# CY8C4xxx register map
File version: 0.1
Registers are 8-bit, read-write, no defined reset value unless marked. A register's access mark holds for its fields unless they carry their own. Offsets are from the block's base; [hi:lo] are bit positions; {n}, {i} and the like mark numbered series; 'fields as' and 'values as' point back to an identical list.

## SAR — SAR ADC with Sequencer
Base 0x401A0000
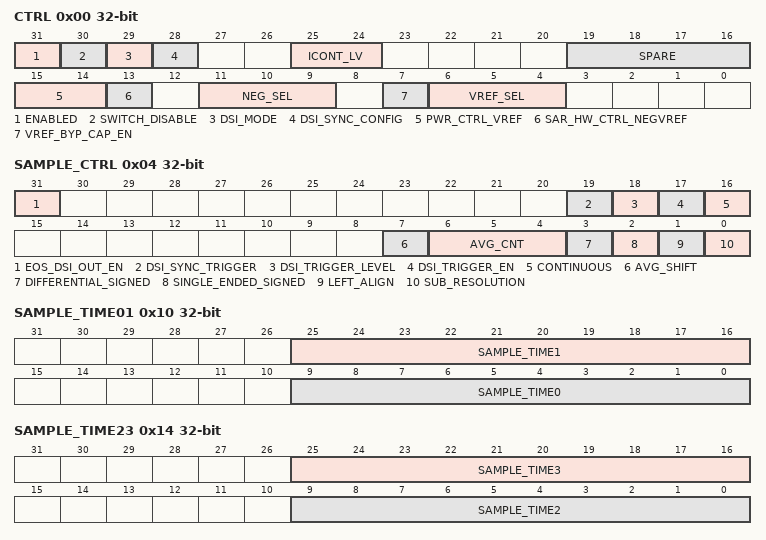
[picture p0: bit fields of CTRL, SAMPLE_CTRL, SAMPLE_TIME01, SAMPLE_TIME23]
0x00 CTRL 32-bit — Analog control register.
  [31] ENABLED — - 0: SAR IP disabled (put analog in power down and stop clocks), also can clear FW_TRIGGER and INJ_START_EN (if not tailgaiting) on write.?- 1: SAR IP enabled.
  [30] SWITCH_DISABLE — Disable SAR sequencer from enabling routing switches (note DSI and firmware can always close switches independent of this control)?- 0: Normal mode, SAR sequencer changes switches according to pin address in channel configurations?- 1: Switches disabled, SAR sequencer does not enable any switches, it is the responsibility of the firmware or UDBs (through DSI) to set the switches to route the signal to be converted through the SARMUX
  [29] DSI_MODE — SAR sequencer takes configuration from DSI signals (note this also has the same effect as SWITCH_DISABLE==1)?- 0: Normal mode, SAR sequencer operates according to CHAN_EN enables and CHAN_CONFIG channel configurations?- 1: CHAN_EN, INJ_START_EN and channel configurations in CHAN_CONFIG and INJ_CHAN_CONFIG are ignored
  [28] DSI_SYNC_CONFIG — - 0: bypass clock domain synchronisation of the DSI config signals.?- 1: synchronize the DSI config signals to peripheral clock domain.
  [25:24] ICONT_LV — SARADC low power mode.
    0=NORMAL_PWR; 1=HALF_PWR; 2=MORE_PWR; 3=QUARTER_PWR
  [19:16] SPARE — Spare controls, not yet designated, for late changes done with an ECO
  [15:14] PWR_CTRL_VREF — VREF buffer low power mode.
    0=NORMAL_PWR; 1=HALF_PWR; 2=THIRD_PWR; 3=QUARTER_PWR
  [13] SAR_HW_CTRL_NEGVREF — Hardware control: 0=only firmware control, 1=hardware control masked by firmware setting for VREF to NEG switch.
  [11:9] NEG_SEL — SARADC internal NEG selection for Single ended conversion
    0=VSSA_KELVIN; 1=ART_VSSA; 2=P1; 3=P3; 4=P5; 5=P7; 6=ACORE; 7=VREF
  [7] VREF_BYP_CAP_EN — VREF bypass cap enable for when VREF buffer is on
  [6:4] VREF_SEL — SARADC internal VREF selection.
    0=VREF0; 1=VREF1; 2=VREF2; 3=VREF_AROUTE; 4=VBGR; 5=VREF_EXT; 6=VDDA_DIV_2; 7=VDDA
0x04 SAMPLE_CTRL 32-bit — Sample control register.
  [31] EOS_DSI_OUT_EN — Enable to output EOS_INTR to DSI. When enabled each time EOS_INTR is set by the hardware also a pulse is send on the dsi_eos signal.
  [19] DSI_SYNC_TRIGGER — - 0: bypass clock domain synchronisation of the DSI trigger signal.?- 1: synchronize the DSI trigger signal to the SAR clock domain, if needed an edge detect is done in the peripheral clock domain.
  [18] DSI_TRIGGER_LEVEL — - 0: DSI trigger signal is a pulse input, a positive edge detected on the DSI trigger signal triggers a new scan.?- 1: DSI trigger signal is a level input, as long as the DSI trigger signal remains high the SAR will do continuous scans.
  [17] DSI_TRIGGER_EN — - 0: firmware trigger only: disable hardware (DSI) trigger.?- 1: enable hardware (DSI) trigger (e.g. from TCPWM, GPIO or UDB).
  [16] CONTINUOUS — - 0: Wait for next FW_TRIGGER (one shot) or hardware (DSI) trigger (e.g. from TPWM for periodic triggering) before scanning enabled channels.?- 1: Continuously scan enabled channels, ignore triggers.
  [7] AVG_SHIFT — Averaging shifting: after averaging the result is shifted right to fit in the sample resolution, i.e. 12 bits.
  [6:4] AVG_CNT — Averaging Count for channels that have over sampling enabled (AVG_EN). A channel will be sampled back to back (1<<(AVG_CNT+1)) = [2..256] times before the result is stored and the next enabled channel is sampled (1st order accumulate and dump filter).?If shifting is not enabled (AVG_SHIFT=0) then the result is forced to shift right so that is fits in 16 bits, so right shift is done by max(0,AVG_CNT-3).
  [3] DIFFERENTIAL_SIGNED — Output data from a differential conversion as a signed value
    0=UNSIGNED; 1=SIGNED
  [2] SINGLE_ENDED_SIGNED — Output data from a single ended conversion as a signed value
    0=UNSIGNED; 1=SIGNED
  [1] LEFT_ALIGN — Left align data in data[15:0], default data is right aligned in data[11:0], with sign extension to 16 bits if the channel is differential.
  [0] SUB_RESOLUTION — Conversion resolution for channels that have sub-resolution enabled (RESOLUTION=1) (otherwise resolution is 12-bit).
    0=Cy8B; 1=Cy10B
0x10 SAMPLE_TIME01 32-bit — Sample time specification ST0 and ST1
  [25:16] SAMPLE_TIME1
  [9:0] SAMPLE_TIME0 — Sample time0 (aperture) in ADC clock cycles.?Minimum sample time is 222ns, which is 4 cycles with an 18MHz clock. Minimum legal value in this register is 1.
0x14 SAMPLE_TIME23 32-bit — Sample time specification ST2 and ST3
  [25:16] SAMPLE_TIME3, [9:0] SAMPLE_TIME2
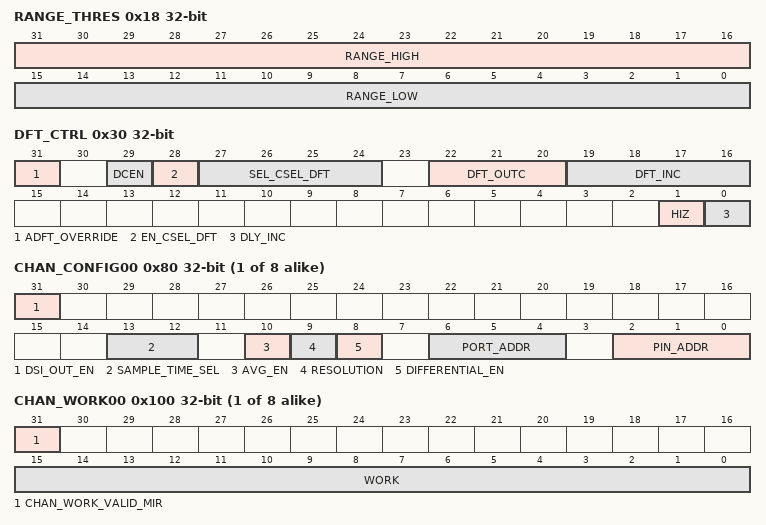
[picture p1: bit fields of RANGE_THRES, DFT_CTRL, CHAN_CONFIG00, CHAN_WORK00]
0x18 RANGE_THRES 32-bit — Global range detect threshold register.
  [31:16] RANGE_HIGH — high threshold for range detect
  [15:0] RANGE_LOW — low threshold for range detect
0x1C RANGE_COND 32-bit — Global range detect mode register.
  [31:30] RANGE_COND — Range condition select.
    0=BELOW; 1=INSIDE; 2=ABOVE; 3=OUTSIDE
0x20 CHAN_EN 32-bit — Enable bits for the channels
  [15:0] CHAN_EN — Channel enable. ?- 0: the corresponding channel is disabled.?- 1: the corresponding channel is enabled, it will be included in the next scan.
0x24 START_CTRL 32-bit — Start control register (firmware trigger).
  [0] FW_TRIGGER write-once — When firmware writes a 1 here it will trigger the next scan of enabled channels, hardware clears this bit when the scan started with this trigger is completed. If scanning continuously the trigger is ignored and hardware clears this bit after the next scan is done. This bit is also cleared when the SAR is disabled.
0x30 DFT_CTRL 32-bit — DFT control register.
  [31] ADFT_OVERRIDE — During deepsleep/ hibernate mode keep SARMUX active, i.e. do not open all switches (disconnect), to be used for ADFT
  [29] DCEN — Delay Control Enable for latch.?- 0: doubles the latch enable time.?- 1: normal latch enable time (default).
  [28] EN_CSEL_DFT — Mux select signal for DAC control
  [27:24] SEL_CSEL_DFT — Usage 1: DFT bits for DAC array?Usage 2: For [0]=1 (when dcen=0): Delay timing for latch enable increased by 20%?[1]=1: comparator preamp power level increased by 25%
  [22:20] DFT_OUTC — DFT control for preamp outputs
  [19:16] DFT_INC — DFT control for preamp inputs
  [1] HIZ — DFT control for getting higher input impedance
  [0] DLY_INC — DFT control: Control for delay circuits on sampling phase, =1 doubes the non-overlap delay
{0x80+4i} CHAN_CONFIG{i:02} 32-bit (i=0..7) — Channel configuration register.
  [31] DSI_OUT_EN — DSI data output enable for this channel.?- 0: the conversion result for this channel is only stored in the channel data register and the corresponding CHAN_DATA_VALID bit is set.?- 1: the conversion result for this channel is stored in the channel data register and the corresponding CHAN_DATA_VALID bit is set. The same data (same formating), together with the channel number, is sent out on the DSI communication channel for processing in UDBs.
  [13:12] SAMPLE_TIME_SEL — Sample time select: select which of the 4 global sample times to use for this channel
  [10] AVG_EN — Averaging enable for this channel. If set the AVG_CNT and AVG_SHIFT settings are used for sampling the addressed pin(s)
  [9] RESOLUTION — Resolution for this channel. When AVG_EN is set this bit is ignored and always a 12-bit resolution is used for this channel.
    0=Cy12B; 1=SUBRES
  [8] DIFFERENTIAL_EN — Differential enable for this channel.?- 0: The voltage on the addressed pin is measured (Single-ended) and the resulting value is stored in the corresponding data register.?- 1: The differential voltage on the addressed pin pair is measured and the resulting value is stored in the corresponding data register. (PIN_ADDR[0] is ignored).
  [6:4] PORT_ADDR — Address of the port that contains the pin to be sampled by this channel.
    0=SARMUX; {v}=CTB{v-1} (v=1..4); 6=AROUTE_VIRT; 7=SARMUX_VIRT
  [2:0] PIN_ADDR — Address of the pin to be sampled by this channel. If differential is enabled then PIN_ADDR[0] is ignored and considered to be 0, i.e. PIN_ADDR points to the even pin of a pin pair.
{0x100+4i} CHAN_WORK{i:02} 32-bit (i=0..7) — Channel working data register
  [31] CHAN_WORK_VALID_MIR ro — mirror bit of corresponding bit in SAR_CHAN_WORK_VALID register
  [15:0] WORK ro — SAR conversion working data of the channel. The data is written here right after sampling this channel.
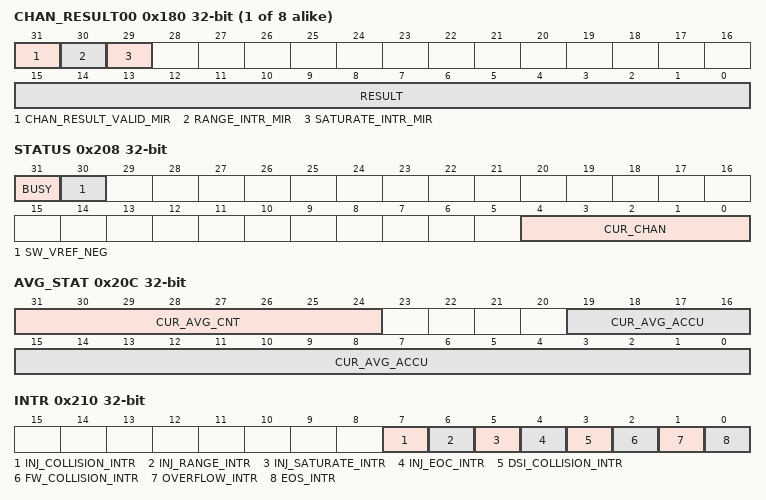
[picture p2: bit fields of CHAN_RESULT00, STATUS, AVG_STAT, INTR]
{0x180+4i} CHAN_RESULT{i:02} 32-bit (i=0..7) — Channel result data register
  [31] CHAN_RESULT_VALID_MIR ro — mirror bit of corresponding bit in SAR_CHAN_RESULT_VALID register
  [30] RANGE_INTR_MIR ro — mirror bit of corresponding bit in SAR_RANGE_INTR register
  [29] SATURATE_INTR_MIR ro — mirror bit of corresponding bit in SAR_SATURATE_INTR register
  [15:0] RESULT ro — SAR conversion result of the channel. The data is copied here from the WORK field after all enabled channels in this scan have been sampled.
0x200 CHAN_WORK_VALID 32-bit — Channel working data register valid bits
  [15:0] CHAN_WORK_VALID ro — If set the corresponding WORK data is valid, i.e. was already sampled during the current scan.
0x204 CHAN_RESULT_VALID 32-bit — Channel result data register valid bits
  [15:0] CHAN_RESULT_VALID ro — If set the corresponding RESULT data is valid, i.e. was sampled during the last scan.
0x208 STATUS 32-bit — Current status of internal SAR registers (mostly for debug)
  [31] BUSY ro — If high then the SAR is busy with a conversion. This bit is always high when CONTINUOUS is set. Firmware should wait for this bit to be low before putting the SAR in power down.
  [30] SW_VREF_NEG ro — the current switch status, including DSI and sequencer controls, of the switch in the SARADC that shorts NEG with VREF input (see NEG_SEL).
  [4:0] CUR_CHAN ro — current channel being sampled (channel 16 indicates the injection channel), only valid if BUSY.
0x20C AVG_STAT 32-bit — Current averaging status (for debug)
  [31:24] CUR_AVG_CNT ro — the current value of the averaging counter. Note that the value shown is updated after the sampling time and therefore runs ahead of the accumulator update.
  [19:0] CUR_AVG_ACCU ro — the current value of the averaging accumulator
0x210 INTR 32-bit — Interrupt request register.
  [7] INJ_COLLISION_INTR write-once — Injection Collision Interrupt: hardware sets this interrupt when the injection trigger signal is asserted (INJ_START_EN==1 && INJ_TAILGATING==0) while the SAR is BUSY. Raising this interrupt is delayed to when the sampling of the injection channel has been completed, i.e. not when the preceeding scan with which this trigger collided is completed. When this interrupt is set it implies that the injection channel was sampled later than was intended. Write with '1' to clear bit.
  [6] INJ_RANGE_INTR write-once — Injection Range detect Interrupt: hardware sets this interrupt if the injection conversion result (after averaging) met the condition specified by the SAR_RANGE registers. Write with '1' to clear bit.
  [5] INJ_SATURATE_INTR write-once — Injection Saturation Interrupt: hardware sets this interrupt if an injection conversion result (before averaging) is either 0x000 or 0xFFF (for 12-bit resolution), this is an indication that the ADC likely saturated. Write with '1' to clear bit.
  [4] INJ_EOC_INTR write-once — Injection End of Conversion Interrupt: hardware sets this interrupt after completing the conversion for the injection channel (irrespective of if tailgating was used). Write with '1' to clear bit.
  [3] DSI_COLLISION_INTR write-once — DSI Collision Interrupt: hardware sets this interrupt when the DSI trigger signal is asserted while the SAR is BUSY. Raising this interrupt is delayed to when the scan caused by the DSI trigger has been completed, i.e. not when the preceeding scan with which this trigger collided is completed. When this interrupt is set it implies that the channels were sampled later than was intended (jitter). Write with '1' to clear bit.
  [2] FW_COLLISION_INTR write-once — Firmware Collision Interrupt: hardware sets this interrupt when FW_TRIGGER is asserted while the SAR is BUSY. Raising this interrupt is delayed to when the scan caused by the FW_TRIGGER has been completed, i.e. not when the preceeding scan with which this trigger collided is completed. When this interrupt is set it implies that the channels were sampled later than was intended (jitter). Write with '1' to clear bit.
  [1] OVERFLOW_INTR write-once — Overflow Interrupt: hardware sets this interrupt when it sets a new EOS_INTR while that bit was not yet cleared by the firmware. Write with '1' to clear bit.
  [0] EOS_INTR write-once — End Of Scan Interrupt: hardware sets this interrupt after completing a scan of all the enabled channels. Write with '1' to clear bit.
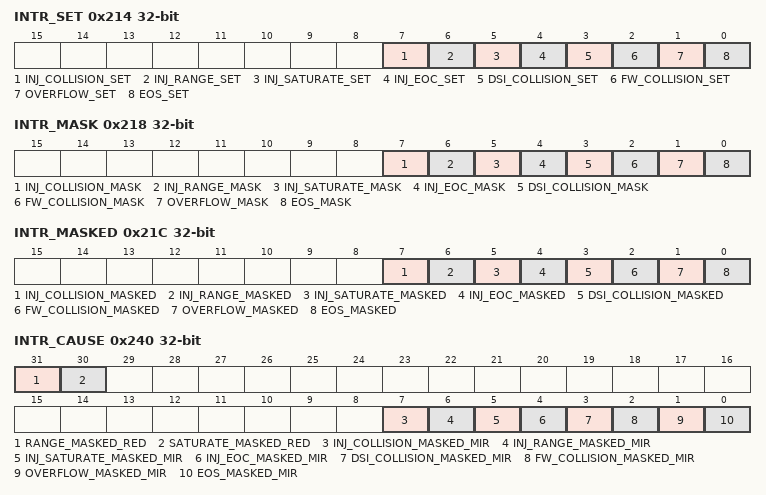
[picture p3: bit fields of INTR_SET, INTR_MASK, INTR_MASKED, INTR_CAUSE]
0x214 INTR_SET 32-bit — Interrupt set request register
  [7] INJ_COLLISION_SET write-once — Write with '1' to set corresponding bit in interrupt request register.
  [6] INJ_RANGE_SET write-once — Write with '1' to set corresponding bit in interrupt request register.
  [5] INJ_SATURATE_SET write-once — Write with '1' to set corresponding bit in interrupt request register.
  [4] INJ_EOC_SET write-once — Write with '1' to set corresponding bit in interrupt request register.
  [3] DSI_COLLISION_SET write-once — Write with '1' to set corresponding bit in interrupt request register.
  [2] FW_COLLISION_SET write-once — Write with '1' to set corresponding bit in interrupt request register.
  [1] OVERFLOW_SET write-once — Write with '1' to set corresponding bit in interrupt request register.
  [0] EOS_SET write-once — Write with '1' to set corresponding bit in interrupt request register.
0x218 INTR_MASK 32-bit — Interrupt mask register.
  [7] INJ_COLLISION_MASK — Mask bit for corresponding bit in interrupt request register.
  [6] INJ_RANGE_MASK — Mask bit for corresponding bit in interrupt request register.
  [5] INJ_SATURATE_MASK — Mask bit for corresponding bit in interrupt request register.
  [4] INJ_EOC_MASK — Mask bit for corresponding bit in interrupt request register.
  [3] DSI_COLLISION_MASK — Mask bit for corresponding bit in interrupt request register.
  [2] FW_COLLISION_MASK — Mask bit for corresponding bit in interrupt request register.
  [1] OVERFLOW_MASK — Mask bit for corresponding bit in interrupt request register.
  [0] EOS_MASK — Mask bit for corresponding bit in interrupt request register.
0x21C INTR_MASKED 32-bit — Interrupt masked request register
  [7] INJ_COLLISION_MASKED ro — Logical and of corresponding request and mask bits.
  [6] INJ_RANGE_MASKED ro — Logical and of corresponding request and mask bits.
  [5] INJ_SATURATE_MASKED ro — Logical and of corresponding request and mask bits.
  [4] INJ_EOC_MASKED ro — Logical and of corresponding request and mask bits.
  [3] DSI_COLLISION_MASKED ro — Logical and of corresponding request and mask bits.
  [2] FW_COLLISION_MASKED ro — Logical and of corresponding request and mask bits.
  [1] OVERFLOW_MASKED ro — Logical and of corresponding request and mask bits.
  [0] EOS_MASKED ro — Logical and of corresponding request and mask bits.
0x220 SATURATE_INTR 32-bit — Saturate interrupt request register.
  [15:0] SATURATE_INTR write-once — Saturate Interrupt: hardware sets this interrupt for each channel if a conversion result (before averaging) of that channel is either 0x000 or 0xFFF (for 12-bit resolution), this is an indication that the ADC likely saturated. Write with '1' to clear bit.
0x224 SATURATE_INTR_SET 32-bit — Saturate interrupt set request register
  [15:0] SATURATE_SET write-once — Write with '1' to set corresponding bit in interrupt request register.
0x228 SATURATE_INTR_MASK 32-bit — Saturate interrupt mask register.
  [15:0] SATURATE_MASK — Mask bit for corresponding bit in interrupt request register.
0x22C SATURATE_INTR_MASKED 32-bit — Saturate interrupt masked request register
  [15:0] SATURATE_MASKED ro — Logical and of corresponding request and mask bits.
0x230 RANGE_INTR 32-bit — Range detect interrupt request register.
  [15:0] RANGE_INTR write-once — Range detect Interrupt: hardware sets this interrupt for each channel if the conversion result (after averaging) of that channel met the condition specified by the SAR_RANGE registers. Write with '1' to clear bit.
0x234 RANGE_INTR_SET 32-bit — Range detect interrupt set request register
  [15:0] RANGE_SET write-once — Write with '1' to set corresponding bit in interrupt request register.
0x238 RANGE_INTR_MASK 32-bit — Range detect interrupt mask register.
  [15:0] RANGE_MASK — Mask bit for corresponding bit in interrupt request register.
0x23C RANGE_INTR_MASKED 32-bit — Range interrupt masked request register
  [15:0] RANGE_MASKED ro — Logical and of corresponding request and mask bits.
0x240 INTR_CAUSE 32-bit — Interrupt cause register
  [31] RANGE_MASKED_RED ro — Reduction OR of all SAR_RANGE_INTR_MASKED bits
  [30] SATURATE_MASKED_RED ro — Reduction OR of all SAR_SATURATION_INTR_MASKED bits
  [7] INJ_COLLISION_MASKED_MIR ro — Mirror copy of corresponding bit in SAR_INTR_MASKED
  [6] INJ_RANGE_MASKED_MIR ro — Mirror copy of corresponding bit in SAR_INTR_MASKED
  [5] INJ_SATURATE_MASKED_MIR ro — Mirror copy of corresponding bit in SAR_INTR_MASKED
  [4] INJ_EOC_MASKED_MIR ro — Mirror copy of corresponding bit in SAR_INTR_MASKED
  [3] DSI_COLLISION_MASKED_MIR ro — Mirror copy of corresponding bit in SAR_INTR_MASKED
  [2] FW_COLLISION_MASKED_MIR ro — Mirror copy of corresponding bit in SAR_INTR_MASKED
  [1] OVERFLOW_MASKED_MIR ro — Mirror copy of corresponding bit in SAR_INTR_MASKED
  [0] EOS_MASKED_MIR ro — Mirror copy of corresponding bit in SAR_INTR_MASKED
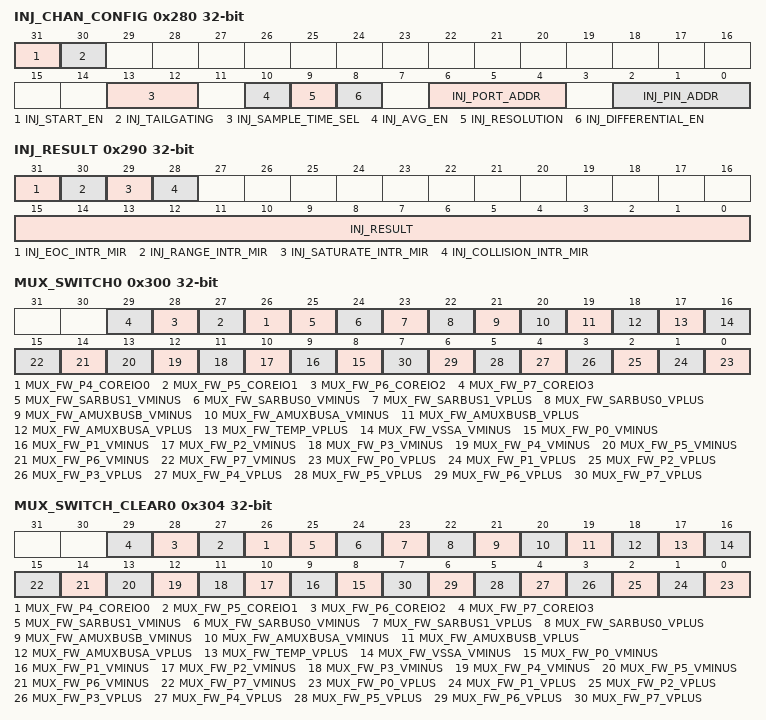
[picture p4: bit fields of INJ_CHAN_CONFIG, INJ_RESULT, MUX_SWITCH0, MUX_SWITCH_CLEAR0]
0x280 INJ_CHAN_CONFIG 32-bit — Injection channel configuration register.
  [31] INJ_START_EN write-once — Set by firmware to enable the injection channel. If INJ_TAILGATING is not set this bit also functions as trigger for this channel. Cleared by hardware after this channel has been sampled (i.e. this channel is always one shot even if CONTINUOUS is set). Also cleared if the SAR is disabled.
  [30] INJ_TAILGATING — Injection channel tailgating.?- 0: no tailgating for this channel, SAR is immediately triggered when the INJ_START_EN bit is set.?- 1: injection channel tailgating. The addressed pin is sampled after the next trigger and after all enabled channels have been scanned.
  [13:12] INJ_SAMPLE_TIME_SEL — Injection sample time select: select which of the 4 global sample times to use for this channel
  [10] INJ_AVG_EN — Averaging enable for this channel. If set the AVG_CNT and AVG_SHIFT settings are used for sampling the addressed pin(s)
  [9] INJ_RESOLUTION — Resolution for this channel.
    0=Cy12B; 1=SUBRES
  [8] INJ_DIFFERENTIAL_EN — Differential enable for this channel.?- 0: The voltage on the addressed pin is measured (Single-ended) and the resulting value is stored in the corresponding data register.?- 1: The differential voltage on the addressed pin pair is measured and the resulting value is stored in the corresponding data register. (INJ_PIN_ADDR[0] is ignored).
  [6:4] INJ_PORT_ADDR — Address of the port that contains the pin to be sampled by this channel.
    values as CHAN_CONFIG00.PORT_ADDR
  [2:0] INJ_PIN_ADDR — Address of the pin to be sampled by this injection channel. If differential is enabled then PIN_ADDR[0] is ignored and considered to be 0, i.e. PIN_ADDR points to the even pin of a pin pair.
0x290 INJ_RESULT 32-bit — Injection channel result register
  [31] INJ_EOC_INTR_MIR ro — mirror bit of corresponding bit in SAR_INTR register
  [30] INJ_RANGE_INTR_MIR ro — mirror bit of corresponding bit in SAR_INTR register
  [29] INJ_SATURATE_INTR_MIR ro — mirror bit of corresponding bit in SAR_INTR register
  [28] INJ_COLLISION_INTR_MIR ro — mirror bit of corresponding bit in SAR_INTR register
  [15:0] INJ_RESULT ro — SAR conversion result of the channel.
0x300 MUX_SWITCH0 32-bit — SARMUX Firmware switch controls
  [n+22] MUX_FW_P{n}_COREIO{n-4} write-once (n=4..7) — Firmware control: 0=open, 1=close switch between P{n} and coreio{n-4} signal. Write with '1' to set bit.
  [25] MUX_FW_SARBUS1_VMINUS write-once — Firmware control: 0=open, 1=close switch between sarbus1 and vminus signal. Write with '1' to set bit.
  [24] MUX_FW_SARBUS0_VMINUS write-once — Firmware control: 0=open, 1=close switch between sarbus0 and vminus signal. Write with '1' to set bit.
  [23] MUX_FW_SARBUS1_VPLUS write-once — Firmware control: 0=open, 1=close switch between sarbus1 and vplus signal. Write with '1' to set bit.
  [22] MUX_FW_SARBUS0_VPLUS write-once — Firmware control: 0=open, 1=close switch between sarbus0 and vplus signal. Write with '1' to set bit.
  [21] MUX_FW_AMUXBUSB_VMINUS write-once — Firmware control: 0=open, 1=close switch between amuxbusb and vminus signal. Write with '1' to set bit.
  [20] MUX_FW_AMUXBUSA_VMINUS write-once — Firmware control: 0=open, 1=close switch between amuxbusa and vminus signal. Write with '1' to set bit.
  [19] MUX_FW_AMUXBUSB_VPLUS write-once — Firmware control: 0=open, 1=close switch between amuxbusb and vplus signal. Write with '1' to set bit.
  [18] MUX_FW_AMUXBUSA_VPLUS write-once — Firmware control: 0=open, 1=close switch between amuxbusa and vplus signal. Write with '1' to set bit.
  [17] MUX_FW_TEMP_VPLUS write-once — Firmware control: 0=open, 1=close switch between temperature sensor and vplus signal, also powers on the temperature sensor. Write with '1' to set bit.
  [16] MUX_FW_VSSA_VMINUS write-once — Firmware control: 0=open, 1=close switch between vssa_kelvin and vminus signal. Write with '1' to set bit.
  [n+8] MUX_FW_P{n}_VMINUS write-once (n=0..7) — Firmware control: 0=open, 1=close switch between pin P{n} and vminus signal. Write with '1' to set bit.
  [n] MUX_FW_P{n}_VPLUS write-once (n=0..7) — Firmware control: 0=open, 1=close switch between pin P{n} and vplus signal. Write with '1' to set bit.
0x304 MUX_SWITCH_CLEAR0 32-bit — SARMUX Firmware switch control clear
  [n+22] MUX_FW_P{n}_COREIO{n-4} write-once (n=4..7) — Write '1' to clear corresponding bit in MUX_SWITCH0
  [25] MUX_FW_SARBUS1_VMINUS write-once — Write '1' to clear corresponding bit in MUX_SWITCH0
  [24] MUX_FW_SARBUS0_VMINUS write-once — Write '1' to clear corresponding bit in MUX_SWITCH0
  [23] MUX_FW_SARBUS1_VPLUS write-once — Write '1' to clear corresponding bit in MUX_SWITCH0
  [22] MUX_FW_SARBUS0_VPLUS write-once — Write '1' to clear corresponding bit in MUX_SWITCH0
  [21] MUX_FW_AMUXBUSB_VMINUS write-once — Write '1' to clear corresponding bit in MUX_SWITCH0
  [20] MUX_FW_AMUXBUSA_VMINUS write-once — Write '1' to clear corresponding bit in MUX_SWITCH0
  [19] MUX_FW_AMUXBUSB_VPLUS write-once — Write '1' to clear corresponding bit in MUX_SWITCH0
  [18] MUX_FW_AMUXBUSA_VPLUS write-once — Write '1' to clear corresponding bit in MUX_SWITCH0
  [17] MUX_FW_TEMP_VPLUS write-once — Write '1' to clear corresponding bit in MUX_SWITCH0
  [16] MUX_FW_VSSA_VMINUS write-once — Write '1' to clear corresponding bit in MUX_SWITCH0
  [n+8] MUX_FW_P{n}_VMINUS write-once (n=0..7) — Write '1' to clear corresponding bit in MUX_SWITCH0
  [n] MUX_FW_P{n}_VPLUS write-once (n=0..7) — Write '1' to clear corresponding bit in MUX_SWITCH0
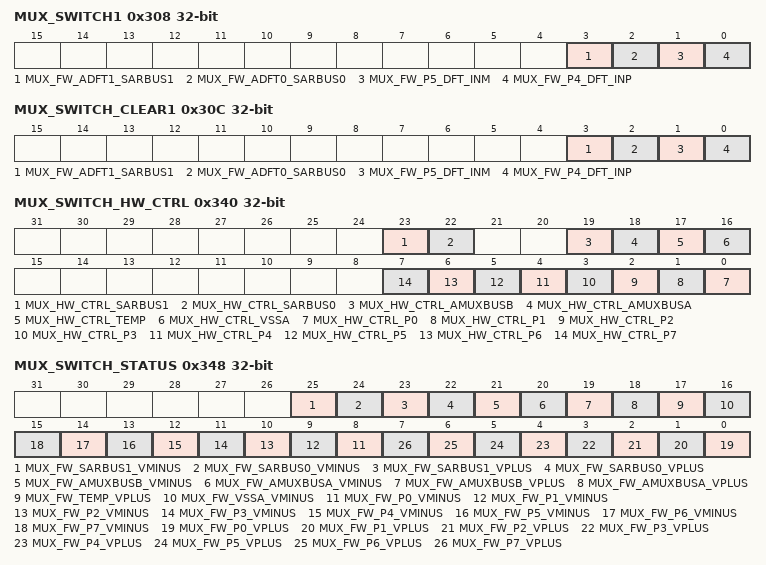
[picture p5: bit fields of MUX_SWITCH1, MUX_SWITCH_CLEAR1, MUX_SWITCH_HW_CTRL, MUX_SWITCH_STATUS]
0x308 MUX_SWITCH1 32-bit — SARMUX Firmware switch controls
  [3] MUX_FW_ADFT1_SARBUS1 write-once — Firmware control: 0=open, 1=close switch between adft1 signal and sarbus1 signal. Write with '1' to set bit.
  [2] MUX_FW_ADFT0_SARBUS0 write-once — Firmware control: 0=open, 1=close switch between adft0 signal and sarbus0 signal. Write with '1' to set bit.
  [1] MUX_FW_P5_DFT_INM write-once — Firmware control: 0=open, 1=close switch between P5 pin and dft_inm signal. Write with '1' to set bit.
  [0] MUX_FW_P4_DFT_INP write-once — Firmware control: 0=open, 1=close switch between P4 pin and dft_inp signal. Write with '1' to set bit.
0x30C MUX_SWITCH_CLEAR1 32-bit — SARMUX Firmware switch control clear
  [3] MUX_FW_ADFT1_SARBUS1 write-once — Write '1' to clear corresponding bit in MUX_SWITCH1
  [2] MUX_FW_ADFT0_SARBUS0 write-once — Write '1' to clear corresponding bit in MUX_SWITCH1
  [1] MUX_FW_P5_DFT_INM write-once — Write '1' to clear corresponding bit in MUX_SWITCH1
  [0] MUX_FW_P4_DFT_INP write-once — Write '1' to clear corresponding bit in MUX_SWITCH1
0x340 MUX_SWITCH_HW_CTRL 32-bit — SARMUX switch hardware control
  [23] MUX_HW_CTRL_SARBUS1 — Hardware control: 0=only firmware control, 1=hardware control masked by firmware setting for sarbus1 switches.
  [22] MUX_HW_CTRL_SARBUS0 — Hardware control: 0=only firmware control, 1=hardware control masked by firmware setting for sarbus0 switches.
  [19] MUX_HW_CTRL_AMUXBUSB — Hardware control: 0=only firmware control, 1=hardware control masked by firmware setting for amuxbusb switches.
  [18] MUX_HW_CTRL_AMUXBUSA — Hardware control: 0=only firmware control, 1=hardware control masked by firmware setting for amuxbusa switches.
  [17] MUX_HW_CTRL_TEMP — Hardware control: 0=only firmware control, 1=hardware control masked by firmware setting for temp switch.
  [16] MUX_HW_CTRL_VSSA — Hardware control: 0=only firmware control, 1=hardware control masked by firmware setting for vssa switch.
  [n] MUX_HW_CTRL_P{n} (n=0..7) — Hardware control: 0=only firmware control, 1=hardware control masked by firmware setting for pin P{n} switches.
0x348 MUX_SWITCH_STATUS 32-bit — SARMUX switch status
  [25] MUX_FW_SARBUS1_VMINUS ro — switch status of corresponding bit in MUX_SWITCH0
  [24] MUX_FW_SARBUS0_VMINUS ro — switch status of corresponding bit in MUX_SWITCH0
  [23] MUX_FW_SARBUS1_VPLUS ro — switch status of corresponding bit in MUX_SWITCH0
  [22] MUX_FW_SARBUS0_VPLUS ro — switch status of corresponding bit in MUX_SWITCH0
  [21] MUX_FW_AMUXBUSB_VMINUS ro — switch status of corresponding bit in MUX_SWITCH0
  [20] MUX_FW_AMUXBUSA_VMINUS ro — switch status of corresponding bit in MUX_SWITCH0
  [19] MUX_FW_AMUXBUSB_VPLUS ro — switch status of corresponding bit in MUX_SWITCH0
  [18] MUX_FW_AMUXBUSA_VPLUS ro — switch status of corresponding bit in MUX_SWITCH0
  [17] MUX_FW_TEMP_VPLUS ro — switch status of corresponding bit in MUX_SWITCH0
  [16] MUX_FW_VSSA_VMINUS ro — switch status of corresponding bit in MUX_SWITCH0
  [n+8] MUX_FW_P{n}_VMINUS ro (n=0..7) — switch status of corresponding bit in MUX_SWITCH0
  [n] MUX_FW_P{n}_VPLUS ro (n=0..7) — switch status of corresponding bit in MUX_SWITCH0
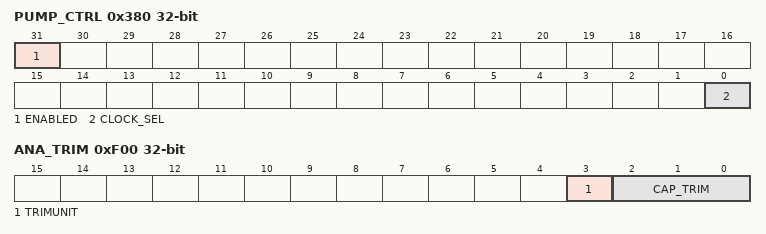
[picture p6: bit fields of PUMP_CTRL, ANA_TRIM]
0x380 PUMP_CTRL 32-bit — Switch pump control
  [31] ENABLED — 0=disabled: pump output is VDDA_PUMP, 1=enabled: pump output is boosted.
  [0] CLOCK_SEL — Clock select: 0=external clock, 1=internal clock (deprecated).
0xF00 ANA_TRIM 32-bit — Analog trim register.
  [3] TRIMUNIT — Attenuation cap trimming
  [2:0] CAP_TRIM — Attenuation cap trimming
0xF04 WOUNDING 32-bit — SAR wounding register
  [1:0] WOUND_RESOLUTION write-once — Maximum SAR resolution allowed
    0=Cy12BIT; 1=Cy10BIT; 2=Cy8BIT; 3=Cy8BIT_TOO
